# MEC1721N_B0_LJ register map
Vendor: Microchip Technology; Series: MEC172x; File version: 0
CPU: CM4 r1p0, little endian, MPU, FPU, 3 interrupt priority bits, 172 interrupts
Registers are 32-bit, read-write, reset 0x0 unless marked. A register's access mark holds for its fields unless they carry their own. Offsets are from the block's base; [hi:lo] are bit positions.

## BC_LINK0 — This block provides BC-Link connectivity to a slave device. The BC-Link protocol includes a start bit to signal the beginning of a message and a turnaround (TAR) period for bus transfer between the Master and Companion devices.
Base 0x4000CD00; register names take the prefix BC_LINK_
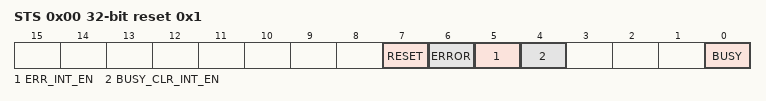
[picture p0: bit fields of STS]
0x00 STS reset 0x1 — BC-Link Status
  [7] RESET — When this bit is '1'the BC_Link Master Interface will be placed in reset and be held in reset until this bit is cleared to '0'. Setting RESET to '1' causes the BUSY bit to be set to '1'. The BUSY remains set to '1' until the reset operation of the BC Interface is completed, which takes approximately 48 BC clocks.
  [6] ERROR — This bit indicates that a BC Bus Error has occurred. (R/WC)
  [5] ERR_INT_EN — This bit is an enable for generating an interrupt when the BC_ERR bit is set by hardware. When this bit is '1', the interrupt signal is enabled. When this bit is '0', the interrupt is disabled.
  [4] BUSY_CLR_INT_EN — This bit is an enable for generating an interrupt when the BUSY bit in this register is cleared by hardware. When this bit is set to '1', the interrupt signal is enabled. When the this bit is cleared to '0', the interrupt is disabled. When enabled, the interrupt occurs after a BC Bus read or write.
  [0] BUSY — This bit is asserted to '1' when the BC interface is transferring data and on reset.
0x04 ADDR — BC-Link Address Register [7:0] Address in the Companion for the BC-Link transaction.
0x08 DATA — BC-Link Data Register [7:0] this register hold data used in a BC-Link transaction.
0x0C CLK_SEL reset 0x4 — BC-Link Clock Select Register [7:0] DIVIDER The BC Clock is set to the Master Clock divided by this field, or 48MHz/ (Divider +1). The clock divider bits can only can be changed when the BC Bus is in soft RESET (when either the Reset bit is set by software or when the BUSY bit is set by the interface).

## PS2_0 — The four PS/2 Ports implementation eliminates the need to bit bang I/O ports to generate PS/2 traffic.
Base 0x40009000; register names take the prefix PS2_
0x00 TX_DATA wo — Writes to bits 7:0 of this register start a transmission of the data in this register to the peripheral
0x00 RX_DATA ro reset 0xFF — Data received from a peripheral are recorded in this register in bits 7:0.
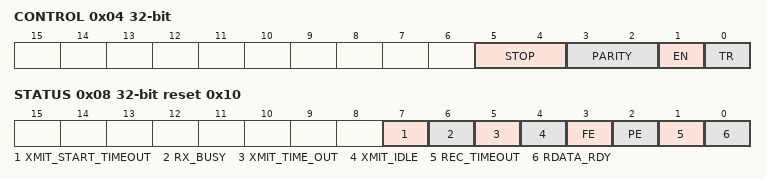
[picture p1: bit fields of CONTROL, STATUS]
0x04 CONTROL — PS2 Control Register
  [5:4] STOP — 00b=Receiver expects an active high stop bit. 01b=Receiver expects an active low stop bit. 10b=Receiver ignores the level of the Stop bit (11th bit is not interpreted as a stop bit). 11b=Reserved.
  [3:2] PARITY — 00b=Receiver expects Odd Parity (default). 01b=Receiver expects Even Parity. 10b=Receiver ignores level of the parity bit (10th bit is not interpreted as a parity bit). 11b=Reserved
  [1] EN — PS/2 Enable. 0=The PS/2 state machine is disabled. 1=The PS/2 state machine is enabled.
  [0] TR — PS/2 Transmit/Receive 0=The P2/2 channel is enabled to receive data. 1=The PS2 channel is enabled to transmit data.
0x08 STATUS reset 0x10 — PS2 Status Register
  [7] XMIT_START_TIMEOUT — Transmit Start Timeout. 0=No transmit start timeout detected 1=A start bit was not received within 25 ms following the transmit start event. The transmit start bit time-out condition is also indicated by the XMIT_TIMEOUT bit.
  [6] RX_BUSY — Receive Channel Busy. 0=The channel is idle 1=The channel is actively receiving PS/2 data
  [5] XMIT_TIME_OUT — Transmitter Time-out. When the XMIT_TIMEOUT bit is set, the PS2_T/R bit is held clear, the PS/2 channel's CLK line is pulled low for a minimum of 300us until the PS/2 Status register is read.
  [4] XMIT_IDLE — Transmitter Idle. 0=The channel is actively transmitting PS/2 data. 1=The channel is not transmitting. A low to high transition on this bit generates a PS2 Activity interrupt.
  [3] FE — Framing Error
  [2] PE — Parity Error
  [1] REC_TIMEOUT — Receive Timeout. The REC_TIMEOUT bit is cleared when the Status Register is read. A low to high transition on this bit generates a PS2 Activity interrupt. (R/WC)
  [0] RDATA_RDY — Receive Data Ready. Reading the Receive Register clears this bit. A low to high transition on this bit generates a PS2 Activity interrupt.
